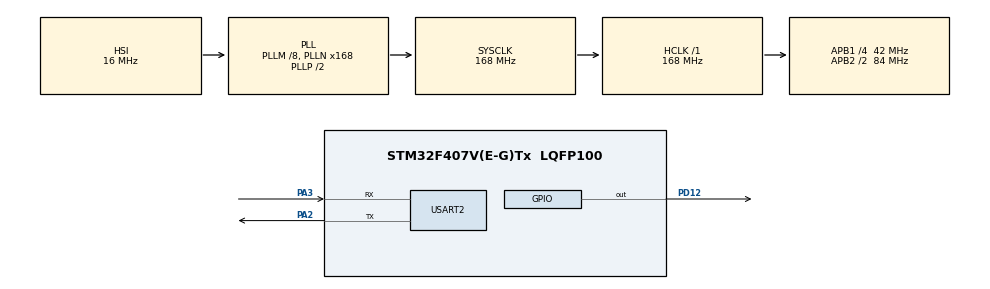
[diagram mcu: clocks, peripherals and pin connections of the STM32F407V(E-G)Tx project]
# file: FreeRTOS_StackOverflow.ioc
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FREERTOS.Tasks01=normalTask,24,128,StartNormalTask,Default,NULL,Dynamic,NULL,NULL;overflowTask,24,128,StartOverflowTask,Default,NULL,Dynamic,NULL,NULL
FREERTOS.configCHECK_FOR_STACK_OVERFLOW=2
FREERTOS.configUSE_NEWLIB_REENTRANT=1
Mcu.Family=STM32F4
Mcu.Name=STM32F407V(E-G)Tx
Mcu.Package=LQFP100
NVIC.PriorityGroup=NVIC_PRIORITYGROUP_4
NVIC.TIM1_UP_TIM10_IRQn=true\:15\:0\:false\:false\:true\:false\:false\:true\:true
NVIC.TimeBase=TIM1_UP_TIM10_IRQn
NVIC.TimeBaseIP=TIM1
PA13.Mode=Serial_Wire
PA13.Signal=SYS_JTMS-SWDIO
PA14.Mode=Serial_Wire
PA14.Signal=SYS_JTCK-SWCLK
PA2.Mode=Asynchronous
PA2.Signal=USART2_TX
PA3.Mode=Asynchronous
PA3.Signal=USART2_RX
PD12.Signal=GPIO_Output
ProjectManager.HeapSize=0x200
ProjectManager.StackSize=0x400
ProjectManager.TargetToolchain=STM32CubeIDE
RCC.48MHZClocksFreq_Value=84000000
RCC.AHBFreq_Value=168000000
RCC.APB1CLKDivider=RCC_HCLK_DIV4
RCC.APB1Freq_Value=42000000
RCC.APB1TimFreq_Value=84000000
RCC.APB2CLKDivider=RCC_HCLK_DIV2
RCC.APB2Freq_Value=84000000
RCC.APB2TimFreq_Value=168000000
RCC.CortexFreq_Value=168000000
RCC.HCLKFreq_Value=168000000
RCC.HSE_VALUE=25000000
RCC.HSI_VALUE=16000000
RCC.LSE_VALUE=32768
RCC.PLLM=8
RCC.PLLN=168
RCC.SYSCLKFreq_VALUE=168000000
RCC.SYSCLKSource=RCC_SYSCLKSOURCE_PLLCLK
RCC.VCOOutputFreq_Value=336000000
USART2.VirtualMode=VM_ASYNC
VP_FREERTOS_VS_CMSIS_V2.Mode=CMSIS_V2
VP_SYS_VS_tim1.Mode=TIM1
board=custom

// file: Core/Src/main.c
/* USER CODE BEGIN Header */
/**
  ******************************************************************************
  * @file           : main.c
  * @brief          : Main program body
  ******************************************************************************
  * @attention
  *
  * Copyright (c) 2026 STMicroelectronics.
  * All rights reserved.
  *
  * This software is licensed under terms that can be found in the LICENSE file
  * in the root directory of this software component.
  * If no LICENSE file comes with this software, it is provided AS-IS.
  *
  ******************************************************************************
  */
/* USER CODE END Header */
#include "main.h"
#include "cmsis_os.h"

/* USER CODE BEGIN Includes */
#include <stdio.h>
/* USER CODE END Includes */

UART_HandleTypeDef huart2;

/* Definitions for normalTask */
osThreadId_t normalTaskHandle;
const osThreadAttr_t normalTask_attributes = {
  .name = "normalTask",
  .stack_size = 128 * 4,
  .priority = (osPriority_t) osPriorityNormal,
};
/* Definitions for overflowTask */
osThreadId_t overflowTaskHandle;
const osThreadAttr_t overflowTask_attributes = {
  .name = "overflowTask",
  .stack_size = 512 * 4,
  .priority = (osPriority_t) osPriorityNormal,
};

void SystemClock_Config(void);
static void MX_GPIO_Init(void);
static void MX_USART2_UART_Init(void);
void StartNormalTask(void *argument);
void StartOverflowTask(void *argument);

int main(void)
{

  /* MCU Configuration--------------------------------------------------------*/

  /* Reset of all peripherals, Initializes the Flash interface and the Systick. */
  HAL_Init();

  /* Configure the system clock */
  SystemClock_Config();

  /* Initialize all configured peripherals */
  MX_GPIO_Init();
  MX_USART2_UART_Init();

  /* Init scheduler */
  osKernelInitialize();

  /* Create the thread(s) */
  /* creation of normalTask */
  normalTaskHandle = osThreadNew(StartNormalTask, NULL, &normalTask_attributes);

  /* creation of overflowTask */
  overflowTaskHandle = osThreadNew(StartOverflowTask, NULL, &overflowTask_attributes);

  /* Start scheduler */
  osKernelStart();

  /* We should never get here as control is now taken by the scheduler */

  /* Infinite loop */
  while (1)
  {

  }
}

void SystemClock_Config(void)
{
  RCC_OscInitTypeDef RCC_OscInitStruct = {0};
  RCC_ClkInitTypeDef RCC_ClkInitStruct = {0};

  /** Configure the main internal regulator output voltage
  */
  __HAL_RCC_PWR_CLK_ENABLE();
  __HAL_PWR_VOLTAGESCALING_CONFIG(PWR_REGULATOR_VOLTAGE_SCALE1);

  /** Initializes the RCC Oscillators according to the specified parameters
  * in the RCC_OscInitTypeDef structure.
  */
  RCC_OscInitStruct.OscillatorType = RCC_OSCILLATORTYPE_HSI;
  RCC_OscInitStruct.HSIState = RCC_HSI_ON;
  RCC_OscInitStruct.HSICalibrationValue = RCC_HSICALIBRATION_DEFAULT;
  RCC_OscInitStruct.PLL.PLLState = RCC_PLL_ON;
  RCC_OscInitStruct.PLL.PLLSource = RCC_PLLSOURCE_HSI;
  RCC_OscInitStruct.PLL.PLLM = 8;
  RCC_OscInitStruct.PLL.PLLN = 168;
  RCC_OscInitStruct.PLL.PLLP = RCC_PLLP_DIV2;
  RCC_OscInitStruct.PLL.PLLQ = 4;
  if (HAL_RCC_OscConfig(&RCC_OscInitStruct) != HAL_OK)
  {
    Error_Handler();
  }

  /** Initializes the CPU, AHB and APB buses clocks
  */
  RCC_ClkInitStruct.ClockType = RCC_CLOCKTYPE_HCLK|RCC_CLOCKTYPE_SYSCLK
                              |RCC_CLOCKTYPE_PCLK1|RCC_CLOCKTYPE_PCLK2;
  RCC_ClkInitStruct.SYSCLKSource = RCC_SYSCLKSOURCE_PLLCLK;
  RCC_ClkInitStruct.AHBCLKDivider = RCC_SYSCLK_DIV1;
  RCC_ClkInitStruct.APB1CLKDivider = RCC_HCLK_DIV4;
  RCC_ClkInitStruct.APB2CLKDivider = RCC_HCLK_DIV2;

  if (HAL_RCC_ClockConfig(&RCC_ClkInitStruct, FLASH_LATENCY_5) != HAL_OK)
  {
    Error_Handler();
  }
}

static void MX_USART2_UART_Init(void)
{

  huart2.Instance = USART2;
  huart2.Init.BaudRate = 115200;
  huart2.Init.WordLength = UART_WORDLENGTH_8B;
  huart2.Init.StopBits = UART_STOPBITS_1;
  huart2.Init.Parity = UART_PARITY_NONE;
  huart2.Init.Mode = UART_MODE_TX_RX;
  huart2.Init.HwFlowCtl = UART_HWCONTROL_NONE;
  huart2.Init.OverSampling = UART_OVERSAMPLING_16;
  if (HAL_UART_Init(&huart2) != HAL_OK)
  {
    Error_Handler();
  }

}

static void MX_GPIO_Init(void)
{
  GPIO_InitTypeDef GPIO_InitStruct = {0};

  /* GPIO Ports Clock Enable */
  __HAL_RCC_GPIOA_CLK_ENABLE();
  __HAL_RCC_GPIOD_CLK_ENABLE();

  /*Configure GPIO pin Output Level */
  HAL_GPIO_WritePin(GPIOD, GPIO_PIN_12, GPIO_PIN_RESET);

  /*Configure GPIO pin : PD12 */
  GPIO_InitStruct.Pin = GPIO_PIN_12;
  GPIO_InitStruct.Mode = GPIO_MODE_OUTPUT_PP;
  GPIO_InitStruct.Pull = GPIO_NOPULL;
  GPIO_InitStruct.Speed = GPIO_SPEED_FREQ_LOW;
  HAL_GPIO_Init(GPIOD, &GPIO_InitStruct);

}

/* USER CODE BEGIN 4 */
int _write(int file, char *ptr, int len)
{
    HAL_UART_Transmit(&huart2, (uint8_t*)ptr, len, HAL_MAX_DELAY);
    return len;
}

/* USER CODE END 4 */

void StartNormalTask(void *argument)
{
  /* USER CODE BEGIN 5 */
  /* Infinite loop */
  for(;;)
  {
	  printf("normalTask running\r\n");
    osDelay(1000);
  }
  /* USER CODE END 5 */
}

void StartOverflowTask(void *argument)
{
  /* USER CODE BEGIN StartOverflowTask */
  /* Infinite loop */
  for(;;)
  {
	  uint8_t bigBuffer[599];  // 600 bytes > 512 byte stack
	      bigBuffer[0] = 0;        // force compiler to actually allocate it
	      printf("overflowTask running\r\n");
	      osDelay(500);
  }
  /* USER CODE END StartOverflowTask */
}

void HAL_TIM_PeriodElapsedCallback(TIM_HandleTypeDef *htim)
{
  if (htim->Instance == TIM1)
  {
    HAL_IncTick();
  }
}

void Error_Handler(void)
{
  __disable_irq();
  while (1)
  {
  }
}

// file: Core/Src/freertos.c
/* USER CODE BEGIN Header */
/**
  ******************************************************************************
  * File Name          : freertos.c
  * Description        : Code for freertos applications
  ******************************************************************************
  * @attention
  *
  * Copyright (c) 2026 STMicroelectronics.
  * All rights reserved.
  *
  * This software is licensed under terms that can be found in the LICENSE file
  * in the root directory of this software component.
  * If no LICENSE file comes with this software, it is provided AS-IS.
  *
  ******************************************************************************
  */
/* USER CODE END Header */

#include "FreeRTOS.h"
#include "task.h"
#include "main.h"

/* USER CODE BEGIN Includes */
#include <stdio.h>
extern UART_HandleTypeDef huart2;
/* USER CODE END Includes */

/* Hook prototypes */
void vApplicationStackOverflowHook(xTaskHandle xTask, signed char *pcTaskName);

/* USER CODE BEGIN 4 */
void vApplicationStackOverflowHook(xTaskHandle xTask, signed char *pcTaskName)
{   char msg[] = "STACK OVERFLOW DETECTED\r\n";
__HAL_RCC_GPIOD_CLK_ENABLE();
HAL_GPIO_WritePin(GPIOD, GPIO_PIN_12, GPIO_PIN_SET);
HAL_UART_Transmit(&huart2, (uint8_t*)msg, sizeof(msg)-1, HAL_MAX_DELAY);
//HAL_GPIO_WritePin(GPIOD, GPIO_PIN_12, GPIO_PIN_SET);
while(1);
   /* Run time stack overflow checking is performed if
   configCHECK_FOR_STACK_OVERFLOW is defined to 1 or 2. This hook function is
   called if a stack overflow is detected. */
}
/* USER CODE END 4 */
